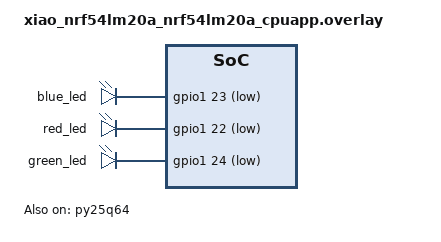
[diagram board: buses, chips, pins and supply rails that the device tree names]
/*
 * Devicetree overlay for the Seeed XIAO nRF54LM20A.
 *
 * Named for the board because a board overlay *replaces* app.overlay rather
 * than adding to it — see common.dtsi, which this includes for the parts
 * every board shares.
 *
 * Seeed's vendored board file defines the on-board PY25Q64H QSPI flash
 * (as `py25q64` on `spi00`) but ships it `status = "disabled"` with no
 * partitions. We flip it on and reserve the entire 8 MiB as a single
 * LittleFS partition — same layout intent as the CONFIG.TXT / firmware /
 * LOG.TXT storage on the nRF52 sibling project, just implemented as a
 * proper filesystem instead of a manually-written FAT12 image.
 */

#include "../common.dtsi"

/*
 * led.c asks for the colours by name rather than by led0/led1/led2, because
 * the numbering is not consistent between XIAOs: here led0 is blue, on
 * xiao_ble led0 is red. Aliasing per board keeps that in the devicetree
 * instead of in a comment nobody reads before swapping boards.
 */
/ {
	aliases {
		blue-led = &blue_led;
		red-led = &red_led;
		green-led = &green_led;
	};
};

&py25q64 {
	status = "okay";

	partitions {
		compatible = "fixed-partitions";
		#address-cells = <1>;
		#size-cells = <1>;

		lfs_partition: partition@0 {
			label = "littlefs_storage";
			reg = <0x00000000 DT_SIZE_M(8)>;
		};
	};
};

/*
 * LED polarity fix.
 *
 * Seeed's vendored board files declare all three LEDs GPIO_ACTIVE_HIGH, and
 * the matching pwmleds nodes PWM_POLARITY_NORMAL. Both are inverted: the XIAO
 * RGB LED is common-anode, so the pin sinks and physical LOW is lit. Every
 * other XIAO in the Zephyr tree agrees — xiao_ble and xiao_nrf54l15 both use
 * GPIO_ACTIVE_LOW (and xiao_ble uses PWM_POLARITY_INVERTED). The same error
 * made twice in one file reads as a copy-paste slip, not a hardware
 * difference, and it is the second thing found wrong in these vendored files
 * after the openocd RRAM commit bug.
 *
 * Symptom it caused: led.c writes are mutually exclusive, but inverted they
 * came out as "red and blue solid, green flickering between them" during DFU,
 * and DONE_OK rendered as magenta rather than solid green.
 *
 * Overridden here rather than in the board file so a board refresh cannot
 * quietly undo it.
 */
&blue_led {
	gpios = <&gpio1 23 GPIO_ACTIVE_LOW>;
};

&red_led {
	gpios = <&gpio1 22 GPIO_ACTIVE_LOW>;
};

&green_led {
	gpios = <&gpio1 24 GPIO_ACTIVE_LOW>;
};

/*
 * Corrected MCUboot slot geometry. Shared with the bootloader image through
 * sysbuild/mcuboot.overlay — see that file for why it is not inline here.
 */
#include "../rram_partitions.dtsi"
